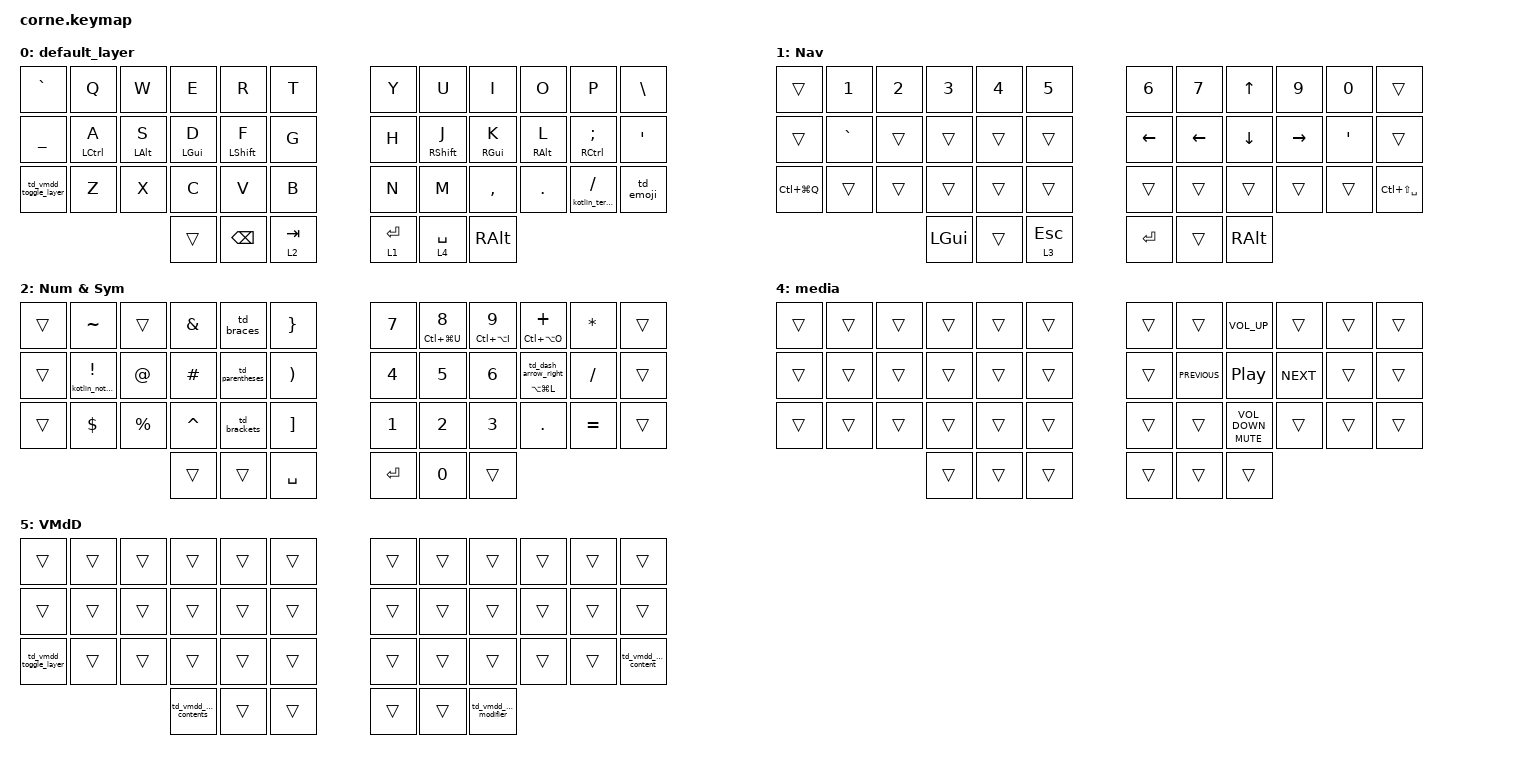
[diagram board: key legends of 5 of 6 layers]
/*
 * Copyright (c) 2020 The ZMK Contributors
 *
 * SPDX-License-Identifier: MIT
 */

#include <behaviors.dtsi>
#include <dt-bindings/zmk/bt.h>
#include <dt-bindings/zmk/keys.h>

&caps_word { continue-list = <UNDERSCORE MINUS>; };

/ {
    behaviors {
        hm: homerow_mods {
            compatible = "zmk,behavior-hold-tap";
            label = "HOMEROW_MODS";
            #binding-cells = <2>;
            tapping-term-ms = <175>;
            flavor = "tap-preferred";
            bindings = <&kp>, <&kp>;

            require-prior-idle-ms = <100>;
        };

        td_braces: td_braces {
            compatible = "zmk,behavior-tap-dance";
            label = "TD_BRACES";
            #binding-cells = <0>;
            bindings = <&kp LEFT_BRACE>, <&open_close_braces>;
        };

        td_parentheses: td_parentheses {
            compatible = "zmk,behavior-tap-dance";
            label = "TD_PARENTHESES";
            #binding-cells = <0>;
            bindings = <&kp LEFT_PARENTHESIS>, <&open_close_parentheses>;
        };

        td_brackets: td_brackets {
            compatible = "zmk,behavior-tap-dance";
            label = "TD_BRACKETS";
            #binding-cells = <0>;
            bindings = <&kp LEFT_BRACKET>, <&open_close_brackets>;
        };

        td_dash_arrow_right: td_dash_arrow_right {
            compatible = "zmk,behavior-tap-dance";
            label = "TD_DASH_ARROW_RIGHT";
            #binding-cells = <0>;
            bindings = <&kp MINUS>, <&dash_arrow_right>;
        };

        td_caps_word_f: td_caps_word_f {
            compatible = "zmk,behavior-tap-dance";
            label = "TD_CAPS_WORD_F";
            #binding-cells = <0>;
            bindings = <&kp F>, <&caps_word>;

            tapping-term-ms = <150>;
        };

        hm_shift_f: hm_shift_f {
            compatible = "zmk,behavior-hold-tap";
            label = "HM_SHIFT_F";
            #binding-cells = <2>;
            tapping-term-ms = <175>;
            flavor = "tap-preferred";
            bindings = <&kp>, <&td_caps_word_f>;

            require-prior-idle-ms = <125>;
        };

        td_caps_word_j: td_caps_word_j {
            compatible = "zmk,behavior-tap-dance";
            label = "TD_CAPS_WORD_J";
            #binding-cells = <0>;
            bindings = <&kp J>, <&caps_word>;

            tapping-term-ms = <150>;
        };

        hm_shift_j: hm_shift_j {
            compatible = "zmk,behavior-hold-tap";
            label = "HM_SHIFT_J";
            #binding-cells = <2>;
            tapping-term-ms = <175>;
            flavor = "tap-preferred";
            bindings = <&kp>, <&td_caps_word_j>;

            require-prior-idle-ms = <125>;
        };

        td_emoji: td_emoji {
            compatible = "zmk,behavior-tap-dance";
            label = "TD_EMOJI";
            #binding-cells = <0>;
            bindings = <&none>, <&kp LC(LG(SPACE))>;
        };

        td_kotlin_ternary_operator: td_kotlin_ternary_operator {
            compatible = "zmk,behavior-hold-tap";
            label = "TD_KOTLIN_TERNARY_OPERATOR";
            bindings = <&kotlin_ternary_operator>, <&kp>;

            #binding-cells = <2>;
            tapping-term-ms = <175>;
            flavor = "tap-preferred";
        };

        htd_dash_arrow_right: htd_dash_arrow_right {
            compatible = "zmk,behavior-hold-tap";
            label = "HTD_DASH_ARROW_RIGHT";
            bindings = <&kp>, <&td_dash_arrow_right>;

            #binding-cells = <2>;
            flavor = "balanced";
            tapping-term-ms = <175>;
        };

        td_vmdd_prepare_contents: td_vmdd_prepare_contents {
            compatible = "zmk,behavior-tap-dance";
            label = "TD_VMDD_PREPARE_CONTENTS";
            #binding-cells = <0>;
            bindings = <&none>, <&kp LG(LS(C))>;
        };

        td_vmdd_prepare_modifier: td_vmdd_prepare_modifier {
            compatible = "zmk,behavior-tap-dance";
            label = "TD_VMDD_PREPARE_MODIFIER";
            #binding-cells = <0>;
            bindings = <&none>, <&kp LG(LS(LA(C)))>;
        };

        td_vmdd_search_content: td_vmdd_search_content {
            compatible = "zmk,behavior-tap-dance";
            label = "TD_VMDD_SEARCH_CONTENT";
            #binding-cells = <0>;
            bindings = <&none>, <&kp LA(LG(LC(SPACE)))>;
        };

        td_vmdd_toggle_layer: td_vmdd_toggle_layer {
            compatible = "zmk,behavior-tap-dance";
            label = "TD_VMDD_TOGGLE_LAYER";
            #binding-cells = <0>;
            bindings = <&kp MINUS>, <&tog 5>;
        };

        td_kotlin_not_equal_comparison: td_kotlin_not_equal_comparison {
            compatible = "zmk,behavior-hold-tap";
            label = "TD_KOTLIN_NOT_EQUAL_COMPARISON";
            bindings = <&kotlin_not_equal_comparison>, <&kp>;

            #binding-cells = <2>;
            tapping-term-ms = <175>;
            flavor = "tap-preferred";
        };
    };

    combos {
        compatible = "zmk,combos";

        combo_caps_word {
            bindings = <&caps_word>;
            key-positions = <16 19>;
        };

        combo_alfred {
            bindings = <&kp LC(SPACE)>;
            key-positions = <38 39>;
            require-prior-idle-ms = <50>;
        };

        combo_clipboard {
            bindings = <&kp LS(LG(V))>;
            key-positions = <37 40>;
            layers = <1 2 3 4 0>;
        };

        GPT {
            bindings = <&kp LC(LA(LG(LS(RETURN))))>;
            key-positions = <39 37>;
        };

        combo_caps_lock {
            bindings = <&kp CAPSLOCK>;
            key-positions = <17 18>;
        };

        context-window-switcher {
            bindings = <&kp LS(LA(LC(LG(SPACE))))>;
            key-positions = <15 20>;
        };

        combo_dash {
            bindings = <&kp MINUS>;
            key-positions = <18 19>;
        };

        combo_clipboard_vmdd {
            bindings = <&vmdd_snippets>;
            key-positions = <37 40>;
            layers = <5>;
        };
    };

    macros {
        open_close_parentheses: open_close_parentheses {
            compatible = "zmk,behavior-macro";
            #binding-cells = <0>;
            bindings = <&kp LEFT_PARENTHESIS &kp RIGHT_PARENTHESIS &kp LEFT>;
            label = "OPEN_CLOSE_PARENTHESES";
        };

        open_close_braces: open_close_braces {
            compatible = "zmk,behavior-macro";
            #binding-cells = <0>;
            bindings = <&kp LEFT_BRACE &kp RIGHT_BRACE &kp LEFT>;
            label = "OPEN_CLOSE_BRACES";
        };

        open_close_brackets: open_close_brackets {
            compatible = "zmk,behavior-macro";
            #binding-cells = <0>;
            bindings = <&kp LEFT_BRACKET &kp RIGHT_BRACKET &kp LEFT>;
            label = "OPEN_CLOSE_BRACKETS";
        };

        dash_arrow_right: dash_arrow_right {
            compatible = "zmk,behavior-macro";
            #binding-cells = <0>;
            bindings = <&kp MINUS &kp GT>;
            label = "DASH_ARROW_RIGHT";
        };

        kotlin_ternary_operator: kotlin_ternary_operator {
            compatible = "zmk,behavior-macro";
            #binding-cells = <0>;
            bindings = <&kp QUESTION &kp COLON>;
            label = "KOTLIN_TERNARY_OPERATOR";
        };

        vmdd_snippets: vmdd_snippets {
            compatible = "zmk,behavior-macro";
            #binding-cells = <0>;
            bindings = <&kp LS(LG(V)) &kp V &kp ENTER>;
            label = "VMDD_SNIPPETS";
            wait-ms = <100>;
        };

        kotlin_not_equal_comparison: kotlin_not_equal_comparison {
            compatible = "zmk,behavior-macro";
            #binding-cells = <0>;
            bindings = <&kp EXCLAMATION &kp EQUAL>;
            label = "KOTLIN_NOT_EQUAL_COMPARISON";
        };
    };

    keymap {
        compatible = "zmk,keymap";

        default_layer {
            // -----------------------------------------------------------------------------------------
            // |  `  |  Q  |  W  |  E  |  R  |  T  |   |  Y  |  U   |  I  |  O  |  P  |  \  |
            // |     |  A  |  S  |  D  |  F  |  G  |   |  H  |  J   |  K  |  L  |  ;  |  '  |
            // |     |  Z  |  X  |  C  |  V  |  B  |   |  N  |  M   |  ,  |  .  |  /  |     |
            //             | GUI | LWR | SPC |   | ENT | RSE  | ALT |

            bindings = <
&kp GRAVE              &kp Q        &kp W           &kp E           &kp R             &kp T        &kp Y        &kp U              &kp I            &kp O            &kp P                                &kp BACKSLASH
&kp UNDERSCORE         &hm LCTRL A  &hm LEFT_ALT S  &hm LEFT_GUI D  &hm LEFT_SHIFT F  &kp G        &kp H        &hm RIGHT_SHIFT J  &hm RIGHT_GUI K  &hm RIGHT_ALT L  &hm RCTRL SEMI                       &kp SQT
&td_vmdd_toggle_layer  &kp Z        &kp X           &kp C           &kp V             &kp B        &kp N        &kp M              &kp COMMA        &kp DOT          &td_kotlin_ternary_operator 0 SLASH  &td_emoji
                                                    &trans          &kp BACKSPACE     &lt 2 TAB    &lt 1 ENTER  &lt 4 SPACE        &kp RALT
            >;
        };

        lower_layer {
            // -----------------------------------------------------------------------------------------
            // |  `  |  1  |  2  |  3  |  4  |  5  |   |  6  |  7  |  8  |  9  |  0  |     |
            // |     |     |     |     |     |     |   | LFT | DWN |  UP | RGT |     |  '  |
            // |     |     |     |     |     |     |   |     |     |     |     |     |     |
            //             | GUI |     | SPC |   | ENT |     | ALT |

            bindings = <
&trans         &kp N1     &kp N2  &kp N3    &kp N4  &kp N5       &kp N6    &kp N7          &kp UP_ARROW    &kp N9     &kp N0          &trans
&trans         &kp GRAVE  &trans  &trans    &trans  &trans       &kp LEFT  &kp LEFT_ARROW  &kp DOWN_ARROW  &kp RIGHT  &kp APOSTROPHE  &trans
&kp LC(LG(Q))  &trans     &trans  &trans    &trans  &trans       &trans    &trans          &trans          &trans     &trans          &kp LC(LS(SPACE))
                                  &kp LGUI  &trans  &lt 3 ESC    &kp RET   &trans          &kp RALT
            >;

            label = "Nav";
        };

        raise_layer {
            // -----------------------------------------------------------------------------------------
            // |     |  !  |  @  |  #  |  $  |  %  |   |  ^  |  &  |  *  |  (  |  )  |     |
            // |     |     |     |     |     |     |   |  -  |  =  |  [  |  ]  |  \  |     |
            // |     |     |     |     |     |     |   |  _  |  +  |  {  |  }  | "|" |     |
            //                    | GUI |     | SPC |   | ENT |     | ALT |

            bindings = <
&trans  &kp TILDE                                      &trans       &kp AMPERSAND  &td_braces       &kp RIGHT_BRACE          &kp N7   &mt LC(LG(U)) N8  &mt LC(LA(I)) N9  &mt LC(LA(O)) PLUS                 &kp ASTERISK  &trans
&trans  &td_kotlin_not_equal_comparison 0 EXCLAMATION  &kp AT       &kp HASH       &td_parentheses  &kp RIGHT_PARENTHESIS    &kp N4   &kp N5            &kp N6            &htd_dash_arrow_right LA(LG(L)) 0  &kp SLASH     &trans
&trans  &kp DOLLAR                                     &kp PERCENT  &kp CARET      &td_brackets     &kp RIGHT_BRACKET        &kp N1   &kp N2            &kp N3            &kp DOT                            &kp EQUAL     &trans
                                                                    &trans         &trans           &kp SPACE                &kp RET  &kp N0            &trans
            >;

            label = "Num & Sym";
        };

        layer_3 {
            bindings = <
&trans  &trans        &trans        &trans        &trans        &trans          &trans      &trans  &trans  &trans  &trans  &trans
&trans  &bt BT_SEL 0  &bt BT_SEL 1  &bt BT_SEL 2  &bt BT_SEL 3  &bt BT_SEL 4    &bt BT_CLR  &trans  &trans  &trans  &trans  &trans
&trans  &trans        &trans        &trans        &trans        &trans          &trans      &trans  &trans  &trans  &trans  &trans
            >;

            label = "BT";
        };

        layer_4 {
            bindings = <
&trans  &trans  &trans  &trans  &trans  &trans    &trans  &trans          &kp K_VOLUME_UP           &trans      &trans  &trans
&trans  &trans  &trans  &trans  &trans  &trans    &trans  &kp C_PREVIOUS  &kp C_PLAY_PAUSE          &kp C_NEXT  &trans  &trans
&trans  &trans  &trans  &trans  &trans  &trans    &trans  &trans          &mt K_MUTE K_VOLUME_DOWN  &trans      &trans  &trans
                        &trans  &trans  &trans    &trans  &trans          &trans
            >;

            label = "media";
        };

        VMdD {
            bindings = <
&trans                 &trans  &trans  &trans                     &trans  &trans    &trans  &trans  &trans                     &trans  &trans  &trans
&trans                 &trans  &trans  &trans                     &trans  &trans    &trans  &trans  &trans                     &trans  &trans  &trans
&td_vmdd_toggle_layer  &trans  &trans  &trans                     &trans  &trans    &trans  &trans  &trans                     &trans  &trans  &td_vmdd_search_content
                                       &td_vmdd_prepare_contents  &trans  &trans    &trans  &trans  &td_vmdd_prepare_modifier
            >;

            label = "VMdD";
        };
    };
};
